# HC32K118 register map
File version: 1.0
CPU: CM0+ r0p1, little endian, no MPU, no FPU, 2 interrupt priority bits
Registers are 32-bit, read-write, reset 0x0 unless marked. A register's access mark holds for its fields unless they carry their own. Offsets are from the block's base; lines under a group give offsets from that group; [hi:lo] are bit positions; {n}, {i} and the like mark numbered series; 'fields as' and 'values as' point back to an identical list; <NAME> marks a mode.

## Memory map
0x01000A00 ICGA size 0x4C
0x40000000 CTC size 0xE
0x40000400 EFM size 0x687
0x40000C00 AOS size 0x174
0x40001800 USART1 size 0x1C — desc USART
0x40001C00 USART2 size 0x1C — desc USART
0x40002000 USART3 size 0x20 — desc USART
0x40002400 USART4 size 0x20 — desc USART
0x40003800 SPI1 size 0x1C — desc SPI
0x40003C00 SPI2 size 0x1C — desc SPI
0x40004800 I2C size 0x34
0x40005400 FCM size 0x24
0x40005800 TMR0 size 0x18
0x40005C00 TMR21 size 0x24 — desc TMR2
0x40006000 TMR22 size 0x24 — desc TMR2
0x40006800 TMR4 size 0xEA
0x40006C00 EMB size 0x1C
0x40007000 TMRA size 0x15E
0x4000B800 ADC size 0xB1
0x4000C800 CMP size 0x16
0x4000CC00 SWDT size 0xC
0x4000D400 RTC size 0x61
0x40010C00 SRAMC size 0x24
0x40011000 INTC size 0x90
0x40011400 MCAN size 0xFC
0x40011800 MCANRAM size 0x18
0x40013000 DMA size 0x110
0x40013400 PERIC size 0x4
0x40013800 GPIO size 0x70E
0x40014000 PWC size 0x41
0x40014100 RMU size 0x2
0x40014400 CMU size 0x41
0x40015000 DBGC size 0x8
0x40015400 CRC size 0x100
0x40017800 ICGB size 0x1F
0xE0042000 DBGC_T size 0x20

## Interrupts
0 EXTINT0_1 (GPIO) — external interrupt 0 or 1
1 EXTINT2_3 (GPIO) — external interrupt 2 or 3
2 EXTINT4_5 (GPIO) — external interrupt 4 or 5
3 EXTINT6_7 (GPIO) — external interrupt 6 or 7
4 DMA — DMA Interrupt
5 EFM — EFM Interrupt
6 TMR0 — Timer0 interrupt
7 TMR2 (TMR21) — Timer2 interrupt
8 TMR4_CMP_OVF_UDF_RELOAD (TMR4) — Timer4 compare overflow underflow reload interrput
9 TMR4_SCMP (TMR4) — Timer4 special compare interrput
10 TMRA — TimerA interrupt
11 USART1_WKUP_RXFULL_TXEMPT (USART1) — USART unit 1 weakup receive full transmit buffer empty interrupt
12 USART1_ERR_TXEND_TXCMPL_RTO (USART1) — USART unit 1 error trans end trans complete or receive timeout interrupt
13 USART2_WKUP_RXFULL_TXEMPT (USART2) — USART unit 2 weakup receive full transmit buffer empty interrupt
14 USART2_ERR_TXEND_TXCMPL_RTO (USART2) — USART unit 2 error transmit end trans complete or receive timeout interrupt
15 USART3_WKUP_RXFULL_TXEMPT (USART3) — USART unit 3 weakup receive full trans buffer empty interrupt
16 USART3_ERR_TXEND_TXCMPL_RTO (USART3) — USART unit 3 error transmit end trans complete or receive timeout interrupt
17 USART4_WKUP_RXFULL_TXEMPT (USART4) — USART unit 4 weakup receive full trans buffer empty interrupt
18 USART4_ERR_TXEND_TXCMPL_RTO (USART4) — USART unit 2 error transmit end trans complete or receive timeout interrupt
19 SPI1_RXFULL_TXEMPTY (SPI1) — SPI unit 1 receive full or transmit buffer empty interrupt
20 SPI1_IDLE_ERROR (SPI1) — SPI unit 1 idle or error interrupt
21 SPI2_RXFULL_TXEMPTY (SPI2) — SPI unit 2 receive full or transmit buffer empty interrupt
22 SPI2_IDLE_ERROR (SPI2) — SPI unit 2 idle or error interrupt
23 I2C_RXFULL_TXEMPTY (I2C) — I2C recevie full or transmit buffer empty interrupt
24 I2C_IDLE_ERROR (I2C) — I2C idle or error interrupt
25 MCAN — MCAN interrupt
26 FCM_CMU (CMU) — CMU or FCM interrupt
27 EMB — EBM interrupt
28 LVD (PWC) — LVD interrupt
29 CMP — CMP interrupt
30 ADC — ADC interrupt

## ADC
Base 0x4000B800
0x00 STR 8-bit
  [0] STRT
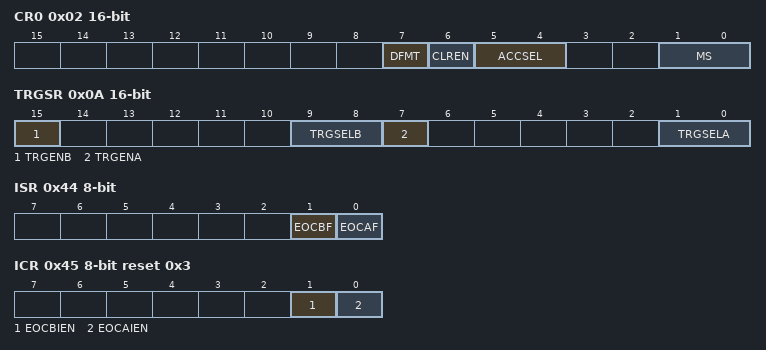
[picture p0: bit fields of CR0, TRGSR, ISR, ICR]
0x02 CR0 16-bit
  [7] DFMT, [6] CLREN, [5:4] ACCSEL, [1:0] MS
0x04 CR1 16-bit
  [2] RSCHSEL
0x0A TRGSR 16-bit
  [15] TRGENB, [9:8] TRGSELB, [7] TRGENA, [1:0] TRGSELA
0x0C CHSELRA 16-bit
  [13:0] CHSELA
0x10 CHSELRB 16-bit
  [13:0] CHSELB
0x18 EXCHSELR 8-bit
  [0] EXCHSEL
0x20 SSTR 8-bit reset 0xB
0x44 ISR 8-bit ro
  [1] EOCBF, [0] EOCAF
0x45 ICR 8-bit reset 0x3
  [1] EOCBIEN, [0] EOCAIEN
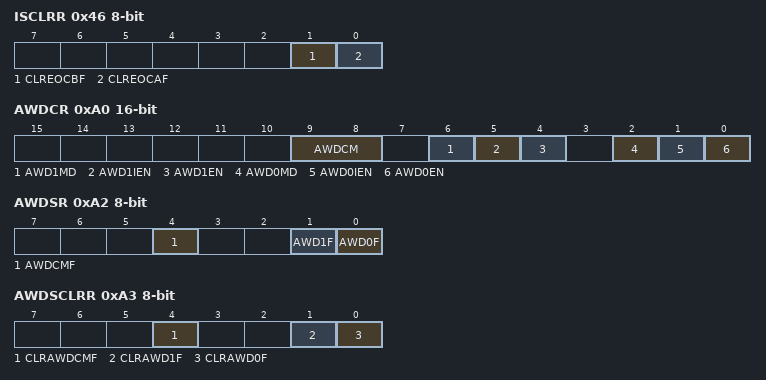
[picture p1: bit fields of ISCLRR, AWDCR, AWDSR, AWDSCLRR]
0x46 ISCLRR 8-bit wo
  [1] CLREOCBF, [0] CLREOCAF
{0x50+2i} DR{i} 16-bit ro (i=0..15)
0xA0 AWDCR 16-bit
  [9:8] AWDCM, [6] AWD1MD, [5] AWD1IEN, [4] AWD1EN, [2] AWD0MD, [1] AWD0IEN, [0] AWD0EN
0xA2 AWDSR 8-bit ro
  [4] AWDCMF, [1] AWD1F, [0] AWD0F
0xA3 AWDSCLRR 8-bit wo
  [4] CLRAWDCMF, [1] CLRAWD1F, [0] CLRAWD0F
0xA4 AWD0DR0 16-bit
0xA6 AWD0DR1 16-bit reset 0xFFFF
0xA8 AWD0CHSR 8-bit
  [4:0] AWDCH
0xAC AWD1DR0 16-bit
0xAE AWD1DR1 16-bit reset 0xFFFF
0xB0 AWD1CHSR 8-bit
  [4:0] AWDCH
